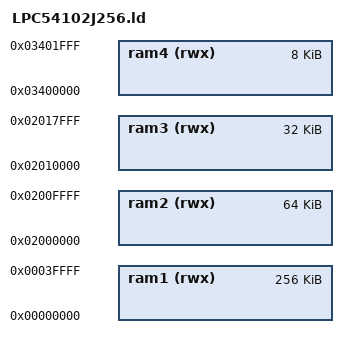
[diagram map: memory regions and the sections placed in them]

MEMORY
{
  ram1 (rwx) : ORIGIN = 0x00000000, LENGTH = 0x040000
  ram2 (rwx) : ORIGIN = 0x02000000, LENGTH = 0x010000
  ram3 (rwx) : ORIGIN = 0x02010000, LENGTH = 0x8000
  ram4 (rwx) : ORIGIN = 0x03400000, LENGTH = 0x2000
}

